# STM32U031xx register map
File version: 1.0
Registers are 32-bit, read-write, reset 0x0 unless marked. A register's access mark holds for its fields unless they carry their own. Offsets are from the block's base; [hi:lo] are bit positions; {n}, {i} and the like mark numbered series.

## PWR — Power Control
Base 0x40007000
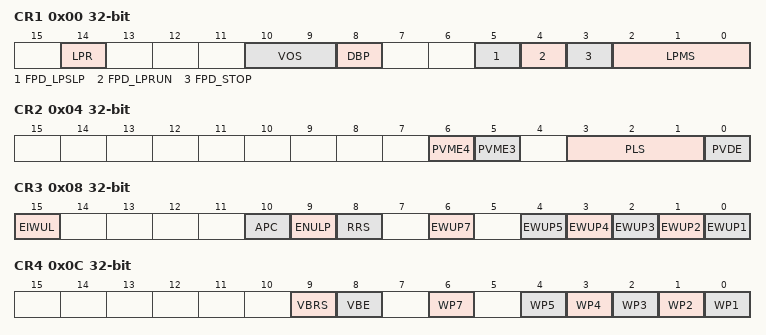
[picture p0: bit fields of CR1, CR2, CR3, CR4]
0x00 CR1 — PWR Power Control Register 1
  [14] LPR — Low Power Run
  [10:9] VOS — VOS[1:0] VOltage Scaling range Selection field
    1=SCALE1; 2=SCALE2
  [8] DBP — Disable backup protection
  [5] FPD_LPSLP — Flash power down mode during low power sleep
  [4] FPD_LPRUN — Flash power down mode during low power run
  [3] FPD_STOP — Flash power down mode during stop
  [2:0] LPMS — LPMS[2:0] Low-power mode selection field
    0=STOP0; 1=STOP1; 2=STOP2; 3=STANDBY; 4=SHUTDOWN
0x04 CR2 — PWR Power Control Register 2
  [6] PVME4 — Peripheral Voltage Monitoring Enable of VDDDAC
  [5] PVME3 — Peripheral Voltage Monitoring Enable of VDDADC
  [3:1] PLS — Power Voltage Detector Level selection
    {v}=PVDLEVEL_{v} (v=0..7)
  [0] PVDE — Programmable Voltage detector enable
0x08 CR3 — PWR Power Control Register 3
  [15] EIWUL — Enable Internal Wake-up line
  [10] APC — Apply pull-up and pull-down configuration
  [9] ENULP — Enable ULP BORL, BORH and PVD (resistor bridge sampling) for STOP2 and all Standby modes
  [8] RRS — Ram retention in STANDBY mode
    0=NO_SRAM_RETENTION; 1=FULL_SRAM_RETENTION
  [6] EWUP7 — Enable external WKUP pin 7
  [n-1] EWUP{n} (n=1..5) — Enable external WKUP pin {n}
0x0C CR4 — PWR Power Control Register 4
  [9] VBRS — VBAT Battery charging Resistor Selection
    0=CHARG_RESISTOR_5K; 1=CHARGRESISTOR_1_5K
  [8] VBE — VBAT Battery charging Enable
  [6] WP7 — Wake-Up pin 7 polarity
  [n-1] WP{n} (n=1..5) — Wake-Up pin {n} polarity
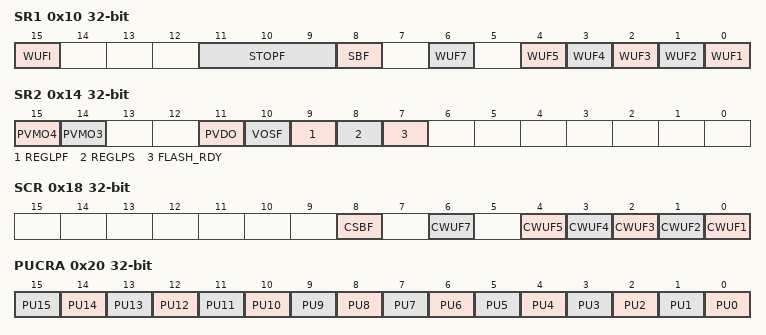
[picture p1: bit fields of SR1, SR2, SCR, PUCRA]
0x10 SR1 — PWR Power Status Register 1
  [15] WUFI — Wakeup Flag Internal
  [11:9] STOPF — STOPF[2:0] Stop Flags
  [8] SBF — Standby Flag
  [6] WUF7 — Wakeup Flag 7
  [n-1] WUF{n} (n=1..5) — Wakeup Flag {n}
0x14 SR2 — PWR Power Status Register 2
  [15] PVMO4 — PVMO DAC & PVME DAC
  [14] PVMO3 — PVMO ADC & PVME ADC
  [11] PVDO — Power Voltage Detector Output
  [10] VOSF — VOltage Scaling Flag
  [9] REGLPF — Regulator Low Power flag
  [8] REGLPS — Regulator Low Power started
  [7] FLASH_RDY — Flash Ready
0x18 SCR — PWR Power Status Reset Register
  [8] CSBF — Clear Standby Flag
  [6] CWUF7 — Clear Wake-up Flag 7
  [n-1] CWUF{n} (n=1..5) — Clear Wake-up Flag {n}
0x20 PUCRA — PWR Pull-Up Control Register of port A
  [n] PU{n} (n=0..15) — Pin PA{n} Pull-Up set
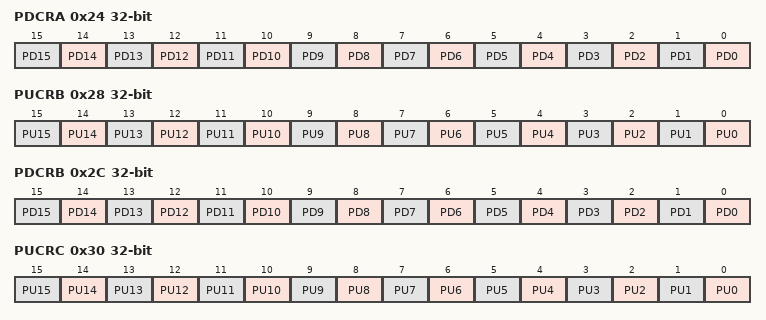
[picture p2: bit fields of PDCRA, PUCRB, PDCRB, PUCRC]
0x24 PDCRA — PWR Pull-Down Control Register of port A
  [n] PD{n} (n=0..15) — Pin PA{n} Pull-Down set
0x28 PUCRB — PWR Pull-Up Control Register of port B
  [n] PU{n} (n=0..15) — Pin PB{n} Pull-Up set
0x2C PDCRB — PWR Pull-Down Control Register of port B
  [n] PD{n} (n=0..15) — Pin PB{n} Pull-Down set
0x30 PUCRC — PWR Pull-Up Control Register of port C
  [n] PU{n} (n=0..15) — Pin PC{n} Pull-Up set
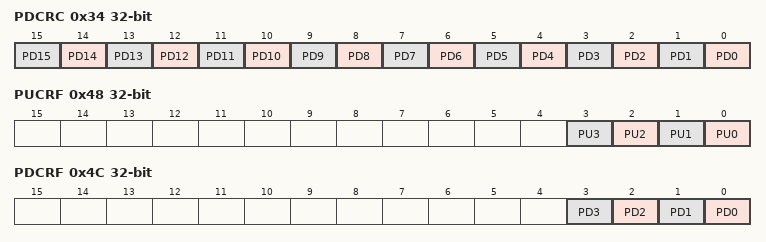
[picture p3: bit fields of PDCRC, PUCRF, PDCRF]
0x34 PDCRC — PWR Pull-Down Control Register of port C
  [n] PD{n} (n=0..15) — Pin PC{n} Pull-Down set
0x38 PUCRD — PWR Pull-Up Control Register of port D
  [2] PU2 — Pin PD2 Pull-Up set
0x3C PDCRD — PWR Pull-Down Control Register of port D
  [2] PD2 — Pin PD2 Pull-Down set
0x48 PUCRF — PWR Pull-Up Control Register of port F
  [n] PU{n} (n=0..3) — Pin PF{n} Pull-Up set
0x4C PDCRF — PWR Pull-Down Control Register of port F
  [n] PD{n} (n=0..3) — Pin PF{n} Pull-Down set

## OPAMP1 — Operational Amplifier (OPAMP)
Base 0x40007800
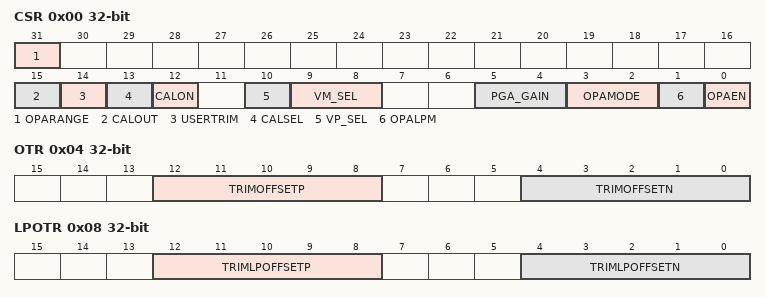
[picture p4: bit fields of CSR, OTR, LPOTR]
0x00 CSR — OPAMP control/status register
  [31] OPARANGE — Operational amplifier range setting
    0=LOW (Power supply range low); 1=HIGH (Power supply range high - recommended for performance purpose)
  [15] CALOUT — Operational amplifier calibration output
  [14] USERTRIM — User trimming enable
    0=FACTORY (OPAMP trimming factors set to factory values); 1=USER (OPAMP trimming factors set to user values)
  [13] CALSEL — Calibration selection
  [12] CALON — Calibration mode enable
    0=FUNCTIONAL (OPAMP functional mode); 1=CALIBRATION (OPAMP calibration mode)
  [10] VP_SEL — Non inverted input selection
    0=NONINVERT_IO0 (OPAMP non inverting input connected to GPIO pin (pin PA0 for OPAMP1)); 1=NONINV_DAC1_CH1 (OPAMP non inverting input connected to DAC1 channel output(channel1 for OPAMP1))
  [9:8] VM_SEL — Inverting input selection
    0=IO0 (OPAMP inverting input connected to GPIO pin (valid also in PGA mode for filtering). Note: OPAMP inverting input is used with OPAMP in mode standalone or PGA with external capacitors for filtering circuit. Otherwise (OPAMP in mode follower), OPAMP inverting input is not used (not connected to GPIO pin).); 2=CONNECT_NO (OPAMP inverting input not externally connected (intended for OPAMP in mode follower or PGA without external capacitors for filtering))
  [5:4] PGA_GAIN — Operational amplifier Programmable amplifier gain value
    0=GAIN_2 (OPAMP PGA gain 2); 1=GAIN_4 (OPAMP PGA gain 4); 2=GAIN_8 (OPAMP PGA gain 8); 3=GAIN_16 (OPAMP PGA gain 16)
  [3:2] OPAMODE — Operational amplifier PGA mode
    0=STANDALONE (OPAMP functional mode, OPAMP operation in standalone); 3=FOLLOWER (OPAMP functional mode, OPAMP operation in follower); 2=PGA (OPAMP functional mode, OPAMP operation in PGA)
  [1] OPALPM — Operational amplifier Low Power Mode
  [0] OPAEN — OPAMP enable
0x04 OTR — OPAMP
  [12:8] TRIMOFFSETP — Trim for PMOS differential pairs
  [4:0] TRIMOFFSETN — Trim for NMOS differential pairs
0x08 LPOTR — OPAMP
  [12:8] TRIMLPOFFSETP — Trim for PMOS differential pairs
  [4:0] TRIMLPOFFSETN — Trim for NMOS differential pairs
